VERSION ""

NS_ :

BS_:

BU_: ADAS_Sensors EPAS ZCU_Front
VAL_TABLE_ vtbSensorReqCause 15 "SNA" 2 "by Request 2" 1 "by Request 1" 0 "normal cycle" ;
VAL_TABLE_ vtbErrorDescription 255 "ERROR" ;

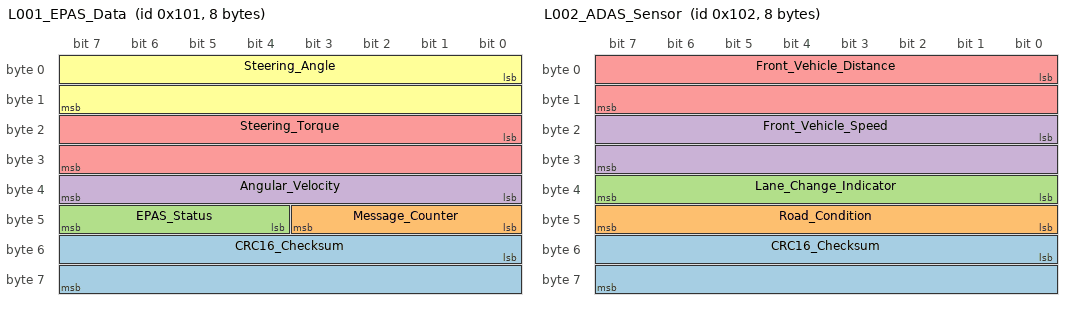
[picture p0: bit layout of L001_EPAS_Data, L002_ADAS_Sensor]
BO_ 257 L001_EPAS_Data: 8 EPAS
 SG_ CRC16_Checksum : 48|16@1+ (1,0) [0|65535] ""  ZCU_Front
 SG_ Message_Counter M : 40|4@1+ (1,0) [0|15] ""  ZCU_Front
 SG_ EPAS_Status : 44|4@1+ (1,0) [0|15] ""  ZCU_Front
 SG_ Angular_Velocity : 32|8@1+ (2,-256) [-256|254] "deg/s"  ZCU_Front
 SG_ Steering_Torque : 16|16@1+ (0.01,-320) [-320|320] "Nm"  ZCU_Front
 SG_ Steering_Angle : 0|16@1+ (0.1,-3200) [-3200|3200] "deg"  ZCU_Front

BO_ 258 L002_ADAS_Sensor: 8 ADAS_Sensors
 SG_ CRC16_Checksum : 48|16@1+ (1,0) [0|65535] ""  ZCU_Front
 SG_ Road_Condition : 40|8@1+ (1,0) [0|255] ""  ZCU_Front
 SG_ Lane_Change_Indicator : 32|8@1+ (1,0) [0|255] ""  ZCU_Front
 SG_ Front_Vehicle_Speed : 16|16@1+ (0.1,0) [0|6553.5] "km/h"  ZCU_Front
 SG_ Front_Vehicle_Distance : 0|16@1+ (0.1,0) [0|6553.5] "m"  ZCU_Front

BA_DEF_ BO_  "VFrameFormat" ENUM  "StandardCAN","ExtendedCAN","reserved","reserved","reserved","reserved","reserved","reserved","reserved","reserved","reserved","reserved","reserved","reserved","StandardCAN_FD","ExtendedCAN_FD";
BA_DEF_  "DatabaseVersion" STRING ;
BA_DEF_  "Manufacturer" STRING ;
BA_DEF_ BU_  "NodeLayerModules" STRING ;
BA_DEF_  "BusType" STRING ;
BA_DEF_ SG_  "GenSigSendType" ENUM  "Cyclic","OnWrite","OnWriteWithRepetition","OnChange","OnChangeWithRepetition","IfActive","IfActiveWithRepetition","NoSigSendType","NotUsed","NotUsed","NotUsed","NotUsed","NotUsed";
BA_DEF_ BO_  "GenMsgSendType" ENUM  "Cyclic","NotUsed","NotUsed","NotUsed","NotUsed","Cyclic","NotUsed","IfActive","NoMsgSendType","NotUsed","vector_leerstring";
BA_DEF_ BO_  "GenMsgCycleTime" INT 0 50000;
BA_DEF_ BO_  "GenMsgCycleTimeFast" INT 0 50000;
BA_DEF_ BO_  "GenMsgILSupport" ENUM  "No","Yes";
BA_DEF_DEF_  "VFrameFormat" "ExtendedCAN_FD";
BA_DEF_DEF_  "DatabaseVersion" "";
BA_DEF_DEF_  "Manufacturer" "Vector";
BA_DEF_DEF_  "NodeLayerModules" "CANoeILNLVector.dll";
BA_DEF_DEF_  "BusType" "CAN";
BA_DEF_DEF_  "GenSigSendType" "Cyclic";
BA_DEF_DEF_  "GenMsgSendType" "NoMsgSendType";
BA_DEF_DEF_  "GenMsgCycleTime" 200;
BA_DEF_DEF_  "GenMsgCycleTimeFast" 20;
BA_DEF_DEF_  "GenMsgILSupport" "Yes";
BA_ "BusType" "CAN FD";
BA_ "DatabaseVersion" "1.1";
BA_ "GenMsgCycleTime" BO_ 257 20;
BA_ "VFrameFormat" BO_ 257 14;
BA_ "GenMsgCycleTime" BO_ 258 50;
BA_ "VFrameFormat" BO_ 258 14;
